# AT32F421 register map
Vendor: Keil; Series: AT32F421; File version: 1.0
CPU: CM4 r0p1, little endian, no MPU, FPU, 4 interrupt priority bits
Registers are 32-bit, read-write, reset 0x0 unless marked. A register's access mark holds for its fields unless they carry their own. Offsets are from the block's base; [hi:lo] are bit positions; {n}, {i} and the like mark numbered series; 'fields as' and 'values as' point back to an identical list.

## CMP — Comparator
Base 0x4001001C
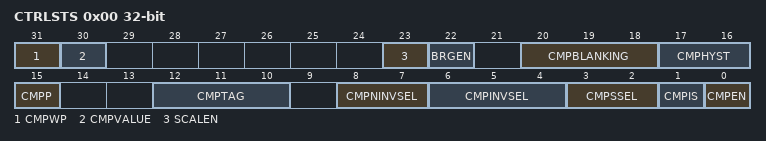
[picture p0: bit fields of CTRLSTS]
0x00 CTRLSTS — CMP control/status register
  [31] CMPWP — Comparator write protect
  [30] CMPVALUE ro — Comparator output value
  [23] SCALEN — Comparator scalen
  [22] BRGEN — Comparator brgen
  [20:18] CMPBLANKING — Comparator blanking
  [17:16] CMPHYST — Comparator hysteresis
  [15] CMPP — Comparator polarity
  [12:10] CMPTAG — Comparator output target
  [8:7] CMPNINVSEL — Comparator non-inverting input selection
  [6:4] CMPINVSEL — Comparator inverting selection
  [3:2] CMPSSEL — Comparator speed selection
  [1] CMPIS — Comparator input shift
  [0] CMPEN — Comparator enable bit
0x08 G_FILTER_EN
  [0] GFE — Glitch filter enable
0x0C HIGH_PULSE
  [5:0] H_PULSE_CNT — High pulse Count
0x10 LOW_PULSE
  [5:0] L_PULSE_CNT — Low pulse Count

## DEBUG — Debug support
Base 0xE0042000
0x00 IDCODE ro — DEBUG_IDCODE
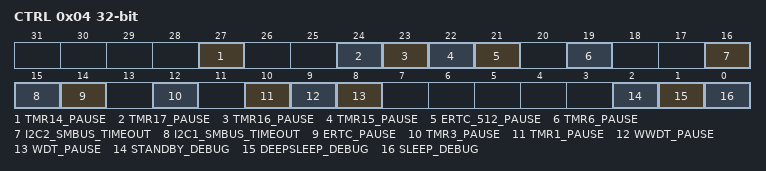
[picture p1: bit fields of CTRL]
0x04 CTRL — DEBUG_CTRL
  [27] TMR14_PAUSE — Timer pause control bit
    0=Continue (The counter clock of TMRx is fed even if the core is halted); 1=Pause (The counter clock of TMRx is stopped when the core is halted)
  [24] TMR17_PAUSE — Timer pause control bit
    values as TMR14_PAUSE
  [23] TMR16_PAUSE — Timer pause control bit
    values as TMR14_PAUSE
  [22] TMR15_PAUSE — Timer pause control bit
    values as TMR14_PAUSE
  [21] ERTC_512_PAUSE
  [19] TMR6_PAUSE — Timer pause control bit
    values as TMR14_PAUSE
  [16] I2C2_SMBUS_TIMEOUT
  [15] I2C1_SMBUS_TIMEOUT
  [14] ERTC_PAUSE
  [12] TMR3_PAUSE — Timer pause control bit
    values as TMR14_PAUSE
  [10] TMR1_PAUSE — Timer pause control bit
    values as TMR14_PAUSE
  [9] WWDT_PAUSE
    values as TMR14_PAUSE
  [8] WDT_PAUSE
    values as TMR14_PAUSE
  [2] STANDBY_DEBUG — Debug Standby mode control bit
    on read: 0=Disabled (The whole 1.2V digital circuit is unpowered in Standby mode); 1=Enabled (The whole 1.2V digital circuit is not unpowered in Standby mode, and the system clock is provided by the internal RC oscillator (HICK)) | on write: 0=Disable (The whole 1.2V digital circuit is unpowered in Standby mode); 1=Enable (The whole 1.2V digital circuit is not unpowered in Standby mode, and the system clock is provided by the internal RC oscillator (HICK))
  [1] DEEPSLEEP_DEBUG — Debug Deepsleep mode control bit
    on read: 0=Disabled (In Deepsleep mode, all clocks in the 1.2V domain are disabled); 1=Enabled (In Deepsleep mode, system clock is provided by the internal RC oscillator (HICK)) | on write: 0=Disable (In Deepsleep mode, all clocks in the 1.2V domain are disabled); 1=Enable (In Deepsleep mode, system clock is provided by the internal RC oscillator (HICK))
  [0] SLEEP_DEBUG — Debug Sleep mode control bit
    on read: 0=Disabled (When entering Sleep mode, CPU HCLK clock is disabled, but other clocks remain active); 1=Enabled (When entering Sleep mode, all clocks keep running) | on write: 0=Disable (When entering Sleep mode, CPU HCLK clock is disabled, but other clocks remain active); 1=Enable (When entering Sleep mode, all clocks keep running)

## CRC — CRC calculation unit
Base 0x40023000
0x00 DT reset 0xFFFFFFFF — Data register
0x04 CDT — Common data register
  [7:0] CDT — Common Data
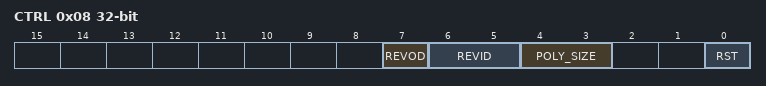
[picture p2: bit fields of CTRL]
0x08 CTRL — Control register
  [7] REVOD — Reverse output data
    0=NoEffect; 1=WordReverse
  [6:5] REVID — Reverse input data
    0=NoEffect; 1=ByteReverse; 2=HalfWordReverse; 3=WordReverse
  [4:3] POLY_SIZE — Polynomial size
    0=bits32 (32 bits); 1=bits16 (16 bits); 2=bits8 (8 bits); 3=bits7 (7 bits)
  [0] RST write-1-sets — Reset bit
    on write: 1=Reset CRC calculation unit, the data register is set as 0xFFFF FFFF
0x10 IDT reset 0xFFFFFFFF — Initial data register
0x14 POLY reset 0x4C11DB7 — Polynomial coefficient register

## NVIC — Nested Vectored Interrupt Controller
Base 0xE000E000
0x04 ICTR ro — Interrupt Controller Type Register
  [3:0] INTLINESNUM — Total number of interrupt lines in groups
0x100 ISER0 — Interrupt Set-Enable Register
  [31:0] SETENA
0x104 ISER1 — Interrupt Set-Enable Register
  [31:0] SETENA
0x180 ICER0 — Interrupt Clear-Enable Register
  [31:0] CLRENA
0x184 ICER1 — Interrupt Clear-Enable Register
  [31:0] CLRENA
0x200 ISPR0 — Interrupt Set-Pending Register
  [31:0] SETPEND
0x204 ISPR1 — Interrupt Set-Pending Register
  [31:0] SETPEND
0x280 ICPR0 — Interrupt Clear-Pending Register
  [31:0] CLRPEND
0x284 ICPR1 — Interrupt Clear-Pending Register
  [31:0] CLRPEND
0x300 IABR0 ro — Interrupt Active Bit Register
  [31:0] ACTIVE
0x304 IABR1 ro — Interrupt Active Bit Register
  [31:0] ACTIVE
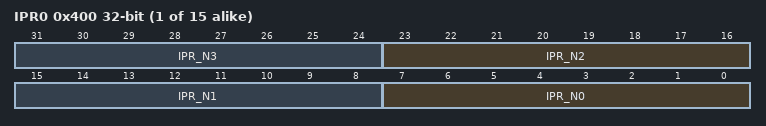
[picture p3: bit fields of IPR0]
{0x400+4i} IPR{i} (i=0..14) — Interrupt Priority Register
  [8n+7:8n] IPR_N{n} (n=0..3)
0xF00 STIR wo — Software Triggered Interrupt Register
  [8:0] INTID — interrupt to be triggered

## SCFG — System configuration controller
Base 0x40010000
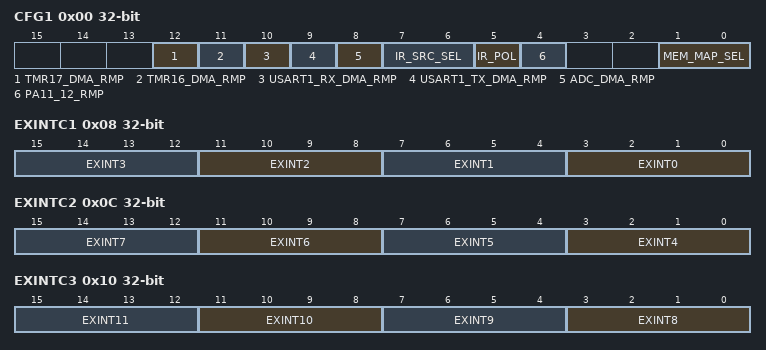
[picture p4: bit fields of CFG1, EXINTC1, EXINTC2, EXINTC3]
0x00 CFG1 — configuration register 1
  [12] TMR17_DMA_RMP — TMR17 DMA remap
  [11] TMR16_DMA_RMP — TMR16 DMA remap
  [10] USART1_RX_DMA_RMP — USART1 receive DMA remap
  [9] USART1_TX_DMA_RMP — USART1 transmit DMA remap
  [8] ADC_DMA_RMP — ADC DMA remap
  [7:6] IR_SRC_SEL — IRTMR source select
  [5] IR_POL — IRTMR Polariyt select
  [4] PA11_12_RMP — PA11 PA12 Remap
  [1:0] MEM_MAP_SEL — Memory address mapping selection bits
0x08 EXINTC1 — external interrupt configuration register 1
  [4n+3:4n] EXINT{n} (n=0..3) — EXINT {n} configuration bits
0x0C EXINTC2 — external interrupt configuration register 2
  [4n-13:4n-16] EXINT{n} (n=4..7) — EXINT {n} configuration bits
0x10 EXINTC3 — external interrupt configuration register 3
  [4n-29:4n-32] EXINT{n} (n=8..11) — EXINT {n} configuration bits
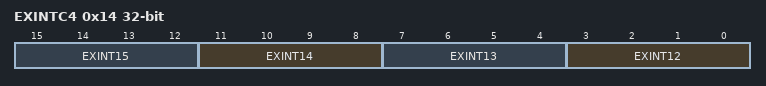
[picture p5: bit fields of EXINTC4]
0x14 EXINTC4 — external interrupt configuration register 4
  [4n-45:4n-48] EXINT{n} (n=12..15) — EXINT {n} configuration bits
